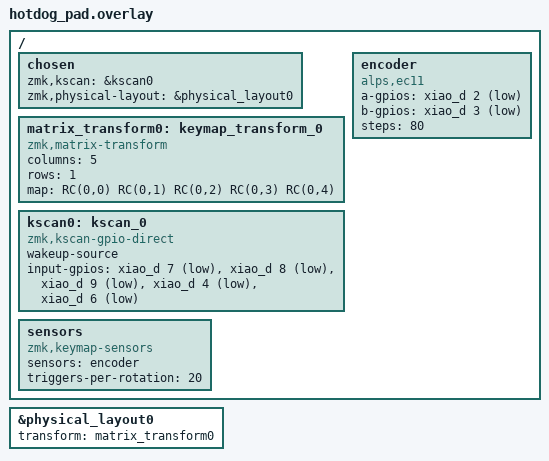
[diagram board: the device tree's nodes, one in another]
/*
* Copyright (c) 2024 Stephen Onnen
*
* SPDX-License-Identifier: MIT
*/

#include <dt-bindings/zmk/matrix_transform.h>
#include "hotdog_pad-layouts.dtsi"

&physical_layout0 {
	transform = <&matrix_transform0>;
};

/ {
	chosen {
		zmk,kscan = &kscan0;
		zmk,physical-layout = &physical_layout0;
	};
	
	matrix_transform0: keymap_transform_0 {
		compatible = "zmk,matrix-transform";
		columns = <5>;
		rows = <1>;
		map = <RC(0,0) RC(0,1) RC(0,2) RC(0,3) RC(0,4)>;
	};
	
	kscan0: kscan_0 {
		compatible = "zmk,kscan-gpio-direct";
		wakeup-source;
		
		input-gpios
		= <&xiao_d 7  (GPIO_ACTIVE_LOW | GPIO_PULL_UP)>
		, <&xiao_d 8  (GPIO_ACTIVE_LOW | GPIO_PULL_UP)>
		, <&xiao_d 9  (GPIO_ACTIVE_LOW | GPIO_PULL_UP)>
		, <&xiao_d 4  (GPIO_ACTIVE_LOW | GPIO_PULL_UP)>
		, <&xiao_d 6  (GPIO_ACTIVE_LOW | GPIO_PULL_UP)>
		;
	};
	
	encoder: encoder {
		compatible = "alps,ec11";
		a-gpios = <&xiao_d 2 (GPIO_ACTIVE_LOW | GPIO_PULL_UP)>;
		b-gpios = <&xiao_d 3 (GPIO_ACTIVE_LOW | GPIO_PULL_UP)>;
		steps = <80>;
		status = "okay";
	};
	
	sensors: sensors {
		compatible = "zmk,keymap-sensors";
		sensors = <&encoder>;
		triggers-per-rotation = <20>;
	};
};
